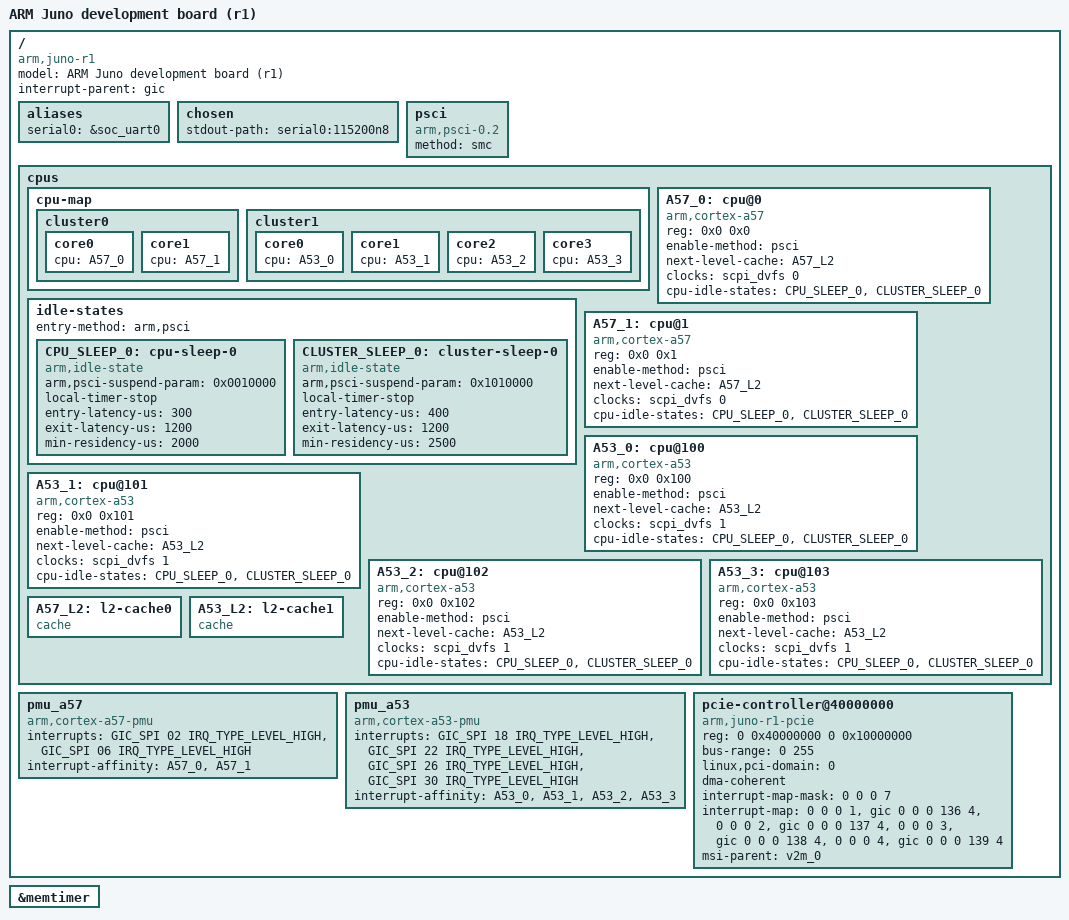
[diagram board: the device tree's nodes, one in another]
/*
 * ARM Ltd. Juno Platform
 *
 * Copyright (c) 2015 ARM Ltd.
 *
 * This file is licensed under a dual GPLv2 or BSD license.
 */

/dts-v1/;

#include <dt-bindings/interrupt-controller/arm-gic.h>

/ {
	model = "ARM Juno development board (r1)";
	compatible = "arm,juno-r1", "arm,juno", "arm,vexpress";
	interrupt-parent = <&gic>;
	#address-cells = <2>;
	#size-cells = <2>;

	aliases {
		serial0 = &soc_uart0;
	};

	chosen {
		stdout-path = "serial0:115200n8";
	};

	psci {
		compatible = "arm,psci-0.2";
		method = "smc";
	};

	cpus {
		#address-cells = <2>;
		#size-cells = <0>;

		cpu-map {
			cluster0 {
				core0 {
					cpu = <&A57_0>;
				};
				core1 {
					cpu = <&A57_1>;
				};
			};

			cluster1 {
				core0 {
					cpu = <&A53_0>;
				};
				core1 {
					cpu = <&A53_1>;
				};
				core2 {
					cpu = <&A53_2>;
				};
				core3 {
					cpu = <&A53_3>;
				};
			};
		};

		idle-states {
			entry-method = "arm,psci";

			CPU_SLEEP_0: cpu-sleep-0 {
				compatible = "arm,idle-state";
				arm,psci-suspend-param = <0x0010000>;
				local-timer-stop;
				entry-latency-us = <300>;
				exit-latency-us = <1200>;
				min-residency-us = <2000>;
			};

			CLUSTER_SLEEP_0: cluster-sleep-0 {
				compatible = "arm,idle-state";
				arm,psci-suspend-param = <0x1010000>;
				local-timer-stop;
				entry-latency-us = <400>;
				exit-latency-us = <1200>;
				min-residency-us = <2500>;
			};
		};

		A57_0: cpu@0 {
			compatible = "arm,cortex-a57","arm,armv8";
			reg = <0x0 0x0>;
			device_type = "cpu";
			enable-method = "psci";
			next-level-cache = <&A57_L2>;
			clocks = <&scpi_dvfs 0>;
			cpu-idle-states = <&CPU_SLEEP_0 &CLUSTER_SLEEP_0>;
		};

		A57_1: cpu@1 {
			compatible = "arm,cortex-a57","arm,armv8";
			reg = <0x0 0x1>;
			device_type = "cpu";
			enable-method = "psci";
			next-level-cache = <&A57_L2>;
			clocks = <&scpi_dvfs 0>;
			cpu-idle-states = <&CPU_SLEEP_0 &CLUSTER_SLEEP_0>;
		};

		A53_0: cpu@100 {
			compatible = "arm,cortex-a53","arm,armv8";
			reg = <0x0 0x100>;
			device_type = "cpu";
			enable-method = "psci";
			next-level-cache = <&A53_L2>;
			clocks = <&scpi_dvfs 1>;
			cpu-idle-states = <&CPU_SLEEP_0 &CLUSTER_SLEEP_0>;
		};

		A53_1: cpu@101 {
			compatible = "arm,cortex-a53","arm,armv8";
			reg = <0x0 0x101>;
			device_type = "cpu";
			enable-method = "psci";
			next-level-cache = <&A53_L2>;
			clocks = <&scpi_dvfs 1>;
			cpu-idle-states = <&CPU_SLEEP_0 &CLUSTER_SLEEP_0>;
		};

		A53_2: cpu@102 {
			compatible = "arm,cortex-a53","arm,armv8";
			reg = <0x0 0x102>;
			device_type = "cpu";
			enable-method = "psci";
			next-level-cache = <&A53_L2>;
			clocks = <&scpi_dvfs 1>;
			cpu-idle-states = <&CPU_SLEEP_0 &CLUSTER_SLEEP_0>;
		};

		A53_3: cpu@103 {
			compatible = "arm,cortex-a53","arm,armv8";
			reg = <0x0 0x103>;
			device_type = "cpu";
			enable-method = "psci";
			next-level-cache = <&A53_L2>;
			clocks = <&scpi_dvfs 1>;
			cpu-idle-states = <&CPU_SLEEP_0 &CLUSTER_SLEEP_0>;
		};

		A57_L2: l2-cache0 {
			compatible = "cache";
		};

		A53_L2: l2-cache1 {
			compatible = "cache";
		};
	};

	pmu_a57 {
		compatible = "arm,cortex-a57-pmu";
		interrupts = <GIC_SPI 02 IRQ_TYPE_LEVEL_HIGH>,
			     <GIC_SPI 06 IRQ_TYPE_LEVEL_HIGH>;
		interrupt-affinity = <&A57_0>,
				     <&A57_1>;
	};

	pmu_a53 {
		compatible = "arm,cortex-a53-pmu";
		interrupts = <GIC_SPI 18 IRQ_TYPE_LEVEL_HIGH>,
			     <GIC_SPI 22 IRQ_TYPE_LEVEL_HIGH>,
			     <GIC_SPI 26 IRQ_TYPE_LEVEL_HIGH>,
			     <GIC_SPI 30 IRQ_TYPE_LEVEL_HIGH>;
		interrupt-affinity = <&A53_0>,
				     <&A53_1>,
				     <&A53_2>,
				     <&A53_3>;
	};

	#include "juno-base.dtsi"

	pcie-controller@40000000 {
		compatible = "arm,juno-r1-pcie", "plda,xpressrich3-axi", "pci-host-ecam-generic";
		device_type = "pci";
		reg = <0 0x40000000 0 0x10000000>;	/* ECAM config space */
		bus-range = <0 255>;
		linux,pci-domain = <0>;
		#address-cells = <3>;
		#size-cells = <2>;
		dma-coherent;
		ranges = <0x01000000 0x00 0x5f800000 0x00 0x5f800000 0x0 0x00800000>,
			 <0x02000000 0x00 0x50000000 0x00 0x50000000 0x0 0x08000000>,
			 <0x42000000 0x40 0x00000000 0x40 0x00000000 0x1 0x00000000>;
		#interrupt-cells = <1>;
		interrupt-map-mask = <0 0 0 7>;
		interrupt-map = <0 0 0 1 &gic 0 0 0 136 4>,
				<0 0 0 2 &gic 0 0 0 137 4>,
				<0 0 0 3 &gic 0 0 0 138 4>,
				<0 0 0 4 &gic 0 0 0 139 4>;
		msi-parent = <&v2m_0>;
	};
};

&memtimer {
	status = "okay";
};
